# N32H49X register map
Vendor: Nsingtech Ltd.; File version: 1.0
Registers are 32-bit, read-write, reset 0x0 unless marked. A register's access mark holds for its fields unless they carry their own. Offsets are from the block's base; [hi:lo] are bit positions; 'fields as' and 'values as' point back to an identical list.

## VREFBUF
Base 0x40021044
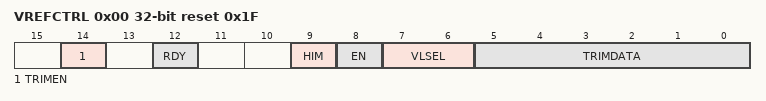
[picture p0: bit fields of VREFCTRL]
0x00 VREFCTRL reset 0x1F
  [14] TRIMEN, [12] RDY, [9] HIM, [8] EN, [7:6] VLSEL, [5:0] TRIMDATA

## DAC12
Base 0x40007C00
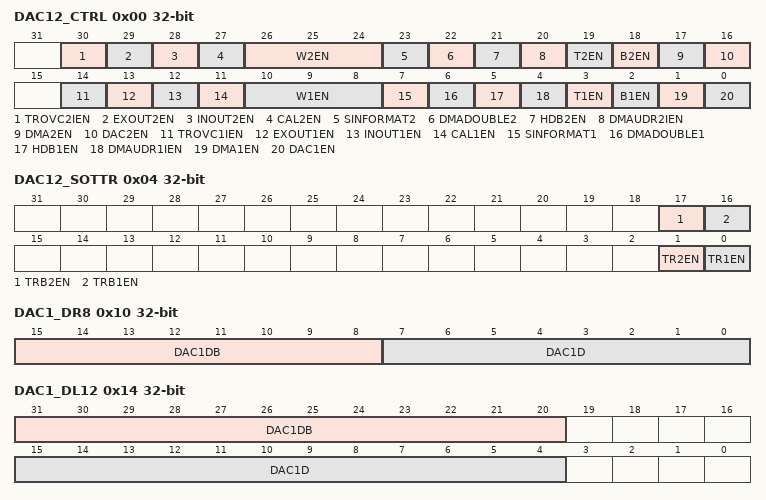
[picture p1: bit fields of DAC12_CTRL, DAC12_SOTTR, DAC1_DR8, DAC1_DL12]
0x00 DAC12_CTRL
  [30] TROVC2IEN, [29] EXOUT2EN, [28] INOUT2EN, [27] CAL2EN, [26:24] W2EN, [23] SINFORMAT2, [22] DMADOUBLE2, [21] HDB2EN, [20] DMAUDR2IEN, [19] T2EN, [18] B2EN, [17] DMA2EN, [16] DAC2EN, [14] TROVC1IEN, [13] EXOUT1EN, [12] INOUT1EN, [11] CAL1EN, [10:8] W1EN, [7] SINFORMAT1, [6] DMADOUBLE1, [5] HDB1EN, [4] DMAUDR1IEN, [3] T1EN, [2] B1EN, [1] DMA1EN, [0] DAC1EN
0x04 DAC12_SOTTR
  [17] TRB2EN, [16] TRB1EN, [1] TR2EN, [0] TR1EN
0x08 DAC1_DATO
  [11:0] DAC1DO
0x0C DAC2_DATO
  [11:0] DAC2DO
0x10 DAC1_DR8
  [15:8] DAC1DB, [7:0] DAC1D
0x14 DAC1_DL12
  [31:20] DAC1DB, [15:4] DAC1D
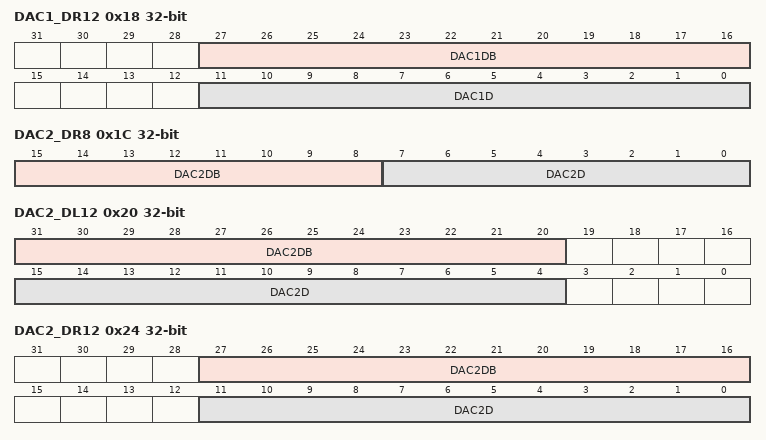
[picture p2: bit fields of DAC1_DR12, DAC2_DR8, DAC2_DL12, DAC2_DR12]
0x18 DAC1_DR12
  [27:16] DAC1DB, [11:0] DAC1D
0x1C DAC2_DR8
  [15:8] DAC2DB, [7:0] DAC2D
0x20 DAC2_DL12
  [31:20] DAC2DB, [15:4] DAC2D
0x24 DAC2_DR12
  [27:16] DAC2DB, [11:0] DAC2D
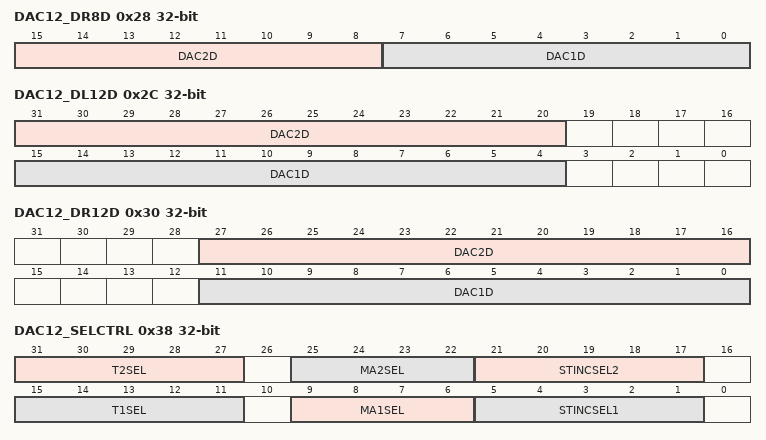
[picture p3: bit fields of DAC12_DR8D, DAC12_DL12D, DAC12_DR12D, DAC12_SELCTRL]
0x28 DAC12_DR8D
  [15:8] DAC2D, [7:0] DAC1D
0x2C DAC12_DL12D
  [31:20] DAC2D, [15:4] DAC1D
0x30 DAC12_DR12D
  [27:16] DAC2D, [11:0] DAC1D
0x38 DAC12_SELCTRL
  [31:27] T2SEL, [25:22] MA2SEL, [21:17] STINCSEL2, [15:11] T1SEL, [9:6] MA1SEL, [5:1] STINCSEL1
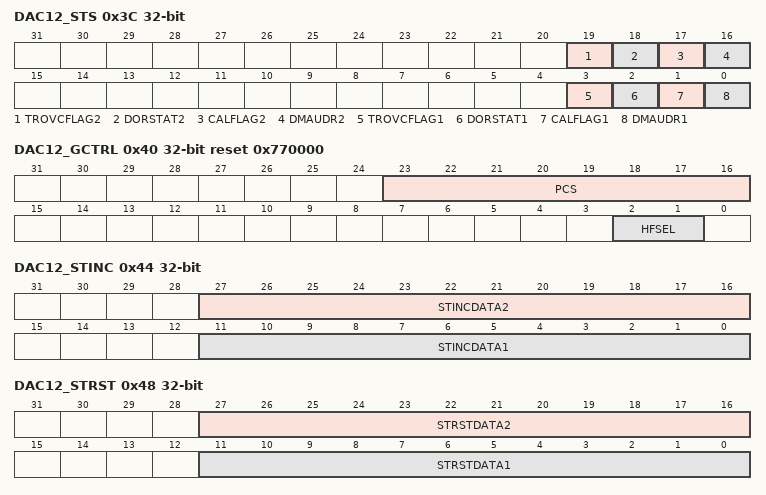
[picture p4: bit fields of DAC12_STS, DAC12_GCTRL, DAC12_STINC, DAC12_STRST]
0x3C DAC12_STS
  [19] TROVCFLAG2, [18] DORSTAT2, [17] CALFLAG2, [16] DMAUDR2, [3] TROVCFLAG1, [2] DORSTAT1, [1] CALFLAG1, [0] DMAUDR1
0x40 DAC12_GCTRL reset 0x770000
  [23:16] PCS, [2:1] HFSEL
0x44 DAC12_STINC
  [27:16] STINCDATA2, [11:0] STINCDATA1
0x48 DAC12_STRST
  [27:16] STRSTDATA2, [11:0] STRSTDATA1
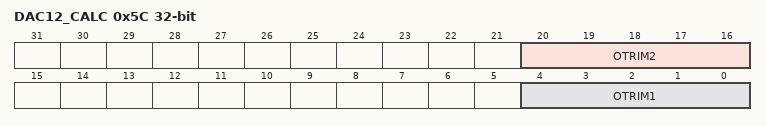
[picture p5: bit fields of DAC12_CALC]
0x5C DAC12_CALC
  [20:16] OTRIM2, [4:0] OTRIM1

## FEMC — Flexible external memory controller
Base 0xA0002000
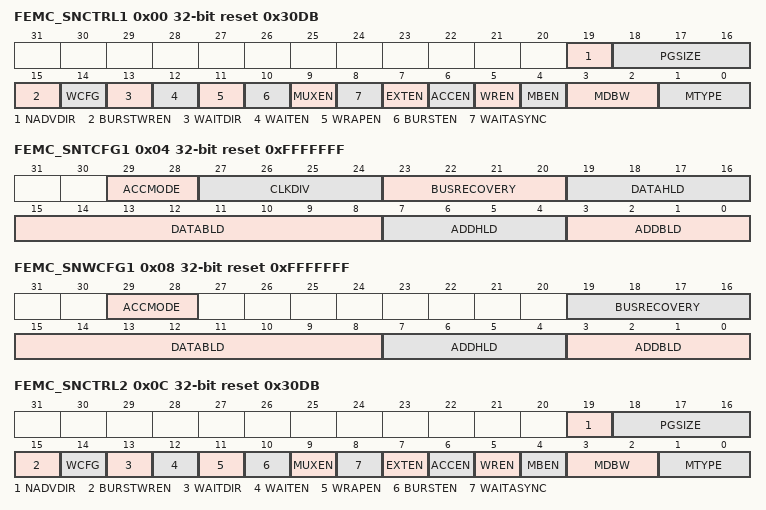
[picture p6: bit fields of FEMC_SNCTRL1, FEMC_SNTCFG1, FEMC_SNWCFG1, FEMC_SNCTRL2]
0x00 FEMC_SNCTRL1 reset 0x30DB
  [19] NADVDIR, [18:16] PGSIZE, [15] BURSTWREN, [14] WCFG, [13] WAITDIR, [12] WAITEN, [11] WRAPEN, [10] BURSTEN, [9] MUXEN, [8] WAITASYNC, [7] EXTEN, [6] ACCEN, [5] WREN, [4] MBEN, [3:2] MDBW, [1:0] MTYPE
0x04 FEMC_SNTCFG1 reset 0xFFFFFFF
  [29:28] ACCMODE, [27:24] CLKDIV, [23:20] BUSRECOVERY, [19:16] DATAHLD, [15:8] DATABLD, [7:4] ADDHLD, [3:0] ADDBLD
0x08 FEMC_SNWCFG1 reset 0xFFFFFFF
  [29:28] ACCMODE, [19:16] BUSRECOVERY, [15:8] DATABLD, [7:4] ADDHLD, [3:0] ADDBLD
0x0C FEMC_SNCTRL2 reset 0x30DB
  fields as FEMC_SNCTRL1
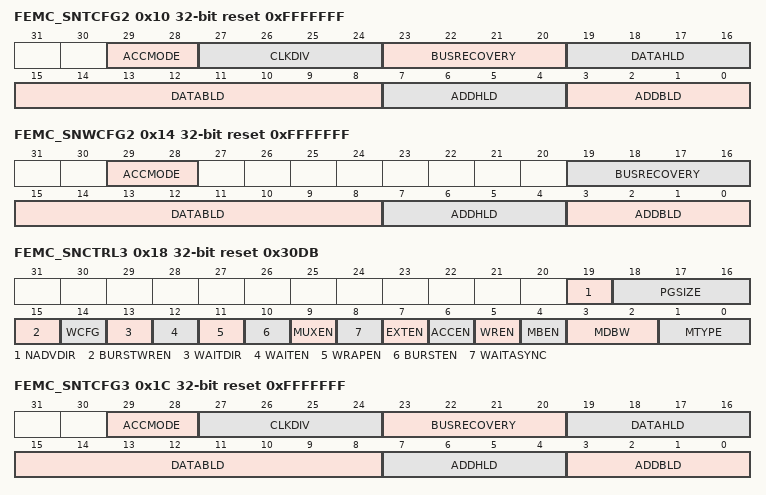
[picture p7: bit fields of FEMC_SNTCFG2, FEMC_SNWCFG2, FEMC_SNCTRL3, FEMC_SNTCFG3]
0x10 FEMC_SNTCFG2 reset 0xFFFFFFF
  fields as FEMC_SNTCFG1
0x14 FEMC_SNWCFG2 reset 0xFFFFFFF
  fields as FEMC_SNWCFG1
0x18 FEMC_SNCTRL3 reset 0x30DB
  fields as FEMC_SNCTRL1
0x1C FEMC_SNTCFG3 reset 0xFFFFFFF
  fields as FEMC_SNTCFG1
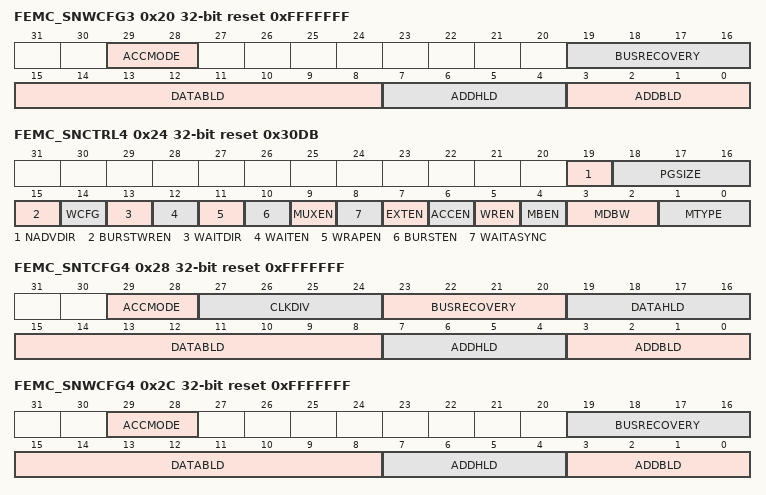
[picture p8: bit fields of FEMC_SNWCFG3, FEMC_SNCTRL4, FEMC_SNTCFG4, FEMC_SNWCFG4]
0x20 FEMC_SNWCFG3 reset 0xFFFFFFF
  fields as FEMC_SNWCFG1
0x24 FEMC_SNCTRL4 reset 0x30DB
  fields as FEMC_SNCTRL1
0x28 FEMC_SNTCFG4 reset 0xFFFFFFF
  fields as FEMC_SNTCFG1
0x2C FEMC_SNWCFG4 reset 0xFFFFFFF
  fields as FEMC_SNWCFG1
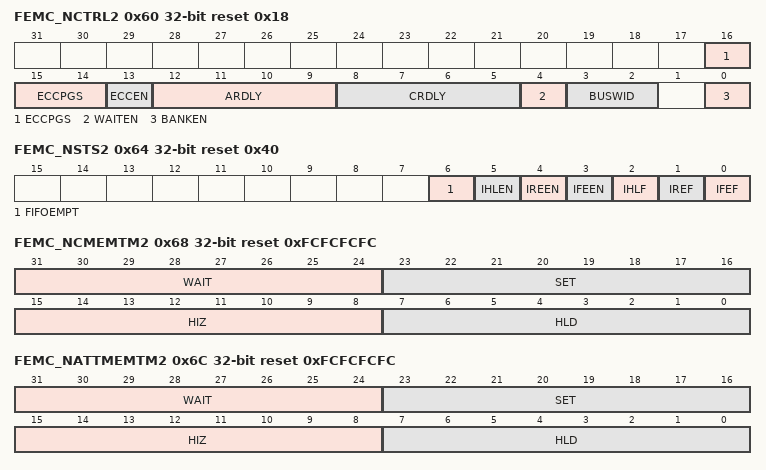
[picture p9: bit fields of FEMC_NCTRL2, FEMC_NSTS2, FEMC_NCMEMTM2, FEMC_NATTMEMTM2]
0x60 FEMC_NCTRL2 reset 0x18 (reset mask 0xFFE7E)
  [16:14] ECCPGS, [13] ECCEN, [12:9] ARDLY, [8:5] CRDLY, [4] WAITEN, [3:2] BUSWID, [0] BANKEN
0x64 FEMC_NSTS2 reset 0x40
  [6] FIFOEMPT, [5] IHLEN, [4] IREEN, [3] IFEEN, [2] IHLF, [1] IREF, [0] IFEF
0x68 FEMC_NCMEMTM2 reset 0xFCFCFCFC
  [31:24] WAIT, [23:16] SET, [15:8] HIZ, [7:0] HLD
0x6C FEMC_NATTMEMTM2 reset 0xFCFCFCFC
  [31:24] WAIT, [23:16] SET, [15:8] HIZ, [7:0] HLD
0x74 FEMC_ECC2 reset 0xFCFCFCFC
  [31:0] ECC
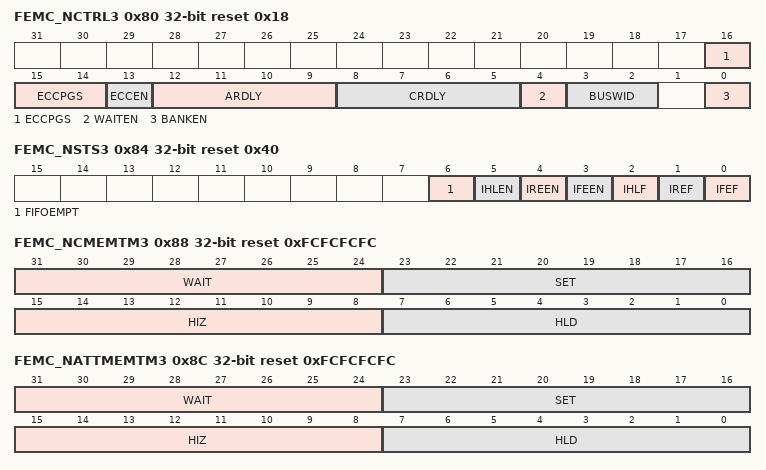
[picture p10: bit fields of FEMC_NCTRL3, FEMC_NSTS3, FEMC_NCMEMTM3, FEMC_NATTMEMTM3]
0x80 FEMC_NCTRL3 reset 0x18 (reset mask 0xFFE7E)
  fields as FEMC_NCTRL2
0x84 FEMC_NSTS3 reset 0x40
  fields as FEMC_NSTS2
0x88 FEMC_NCMEMTM3 reset 0xFCFCFCFC
  [31:24] WAIT, [23:16] SET, [15:8] HIZ, [7:0] HLD
0x8C FEMC_NATTMEMTM3 reset 0xFCFCFCFC
  [31:24] WAIT, [23:16] SET, [15:8] HIZ, [7:0] HLD
0x94 FEMC_ECC3 reset 0xFCFCFCFC
  [31:0] ECC

## FMAC — Filter math accelerator
Base 0x40021C00
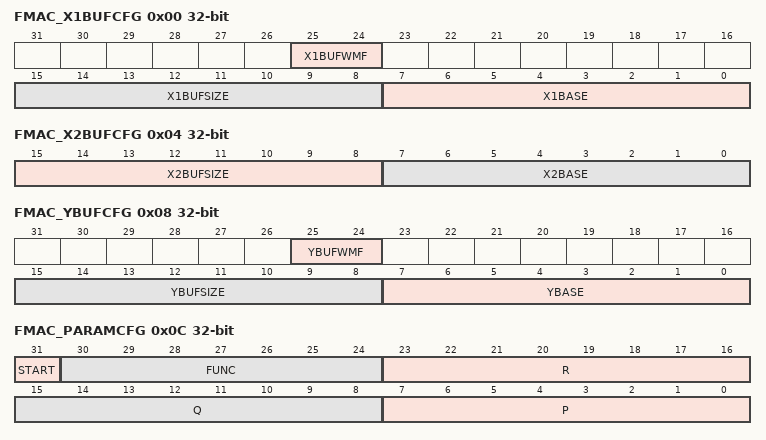
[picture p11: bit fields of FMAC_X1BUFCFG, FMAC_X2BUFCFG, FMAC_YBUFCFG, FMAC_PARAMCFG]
0x00 FMAC_X1BUFCFG
  [25:24] X1BUFWMF, [15:8] X1BUFSIZE, [7:0] X1BASE
0x04 FMAC_X2BUFCFG
  [15:8] X2BUFSIZE, [7:0] X2BASE
0x08 FMAC_YBUFCFG
  [25:24] YBUFWMF, [15:8] YBUFSIZE, [7:0] YBASE
0x0C FMAC_PARAMCFG
  [31] START, [30:24] FUNC, [23:16] R, [15:8] Q, [7:0] P
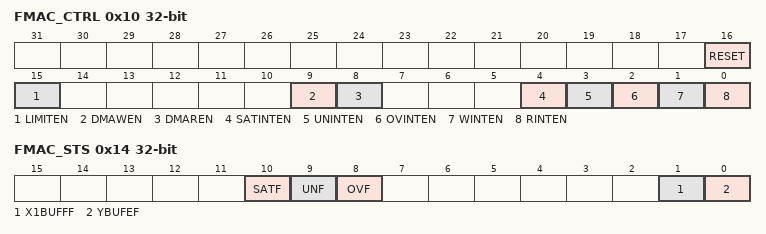
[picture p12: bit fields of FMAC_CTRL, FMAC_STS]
0x10 FMAC_CTRL
  [16] RESET, [15] LIMITEN, [9] DMAWEN, [8] DMAREN, [4] SATINTEN, [3] UNINTEN, [2] OVINTEN, [1] WINTEN, [0] RINTEN
0x14 FMAC_STS
  [10] SATF, [9] UNF, [8] OVF, [1] X1BUFFF, [0] YBUFEF
0x18 FMAC_WDAT
  [15:0] WDAT
0x1C FMAC_RDAT
  [15:0] RDAT
